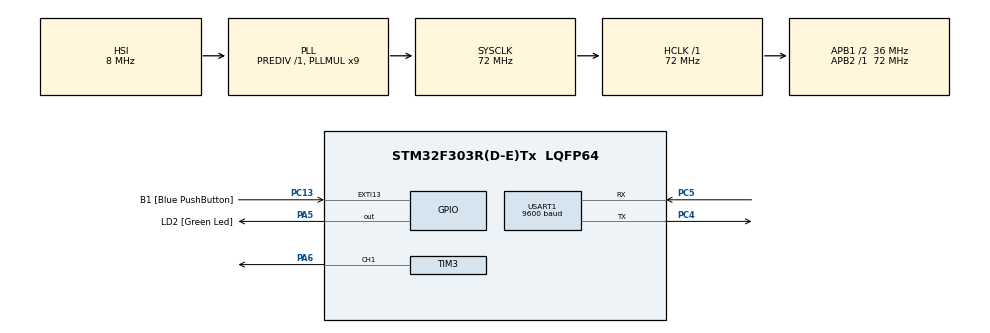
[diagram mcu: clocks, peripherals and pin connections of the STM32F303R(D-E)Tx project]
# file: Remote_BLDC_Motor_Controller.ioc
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Mcu.Family=STM32F3
PC15-OSC32_OUT.Mode=LSE-External-Oscillator
RCC.CortexFreq_Value=72000000
TIM3.AutoReloadPreload=TIM_AUTORELOAD_PRELOAD_ENABLE
USART1.BaudRate=9600
PC13.Signal=GPXTI13
PA14.GPIO_Label=TCK
RCC.SYSCLKSourceVirtual=RCC_SYSCLKSOURCE_PLLCLK
PC4.Signal=USART1_TX
PC5.Mode=Asynchronous
PC13.GPIO_Label=B1 [Blue PushButton]
RCC.APB1CLKDivider=RCC_HCLK_DIV2
PC14-OSC32_IN.Signal=RCC_OSC32_IN
ProjectManager.StackSize=0x400
USART1.VirtualMode-Asynchronous=VM_ASYNC
PA13.Signal=SYS_JTMS-SWDIO
ProjectManager.TargetToolchain=STM32CubeIDE
RCC.HCLKFreq_Value=72000000
RCC.APB2TimFreq_Value=72000000
TIM3.Period=19999
RCC.USBFreq_Value=72000000
PC15-OSC32_OUT.Signal=RCC_OSC32_OUT
RCC.AHBFreq_Value=72000000
PF0-OSC_IN.Mode=HSE-External-Clock-Source
TIM3.Channel-PWM\ Generation1\ CH1=TIM_CHANNEL_1
PA5.Signal=GPIO_Output
RCC.HSE_VALUE=8000000
board=NUCLEO-F303RE
RCC.RCC_PLLsource_Clock_Source_FROM_HSE=RCC_HSE_PREDIV_DIV2
RCC.PLLMUL=RCC_PLL_MUL9
RCC.APB2Freq_Value=72000000
PC14-OSC32_IN.Mode=LSE-External-Oscillator
PA14.Mode=Serial_Wire
TIM3.Prescaler=71
PA5.GPIO_PuPd=GPIO_NOPULL
SH.S_TIM3_CH1.0=TIM3_CH1,PWM Generation1 CH1
PA13.Mode=Serial_Wire
Mcu.Name=STM32F303R(D-E)Tx
PA13.GPIO_Label=TMS
PB3.Signal=SYS_JTDO-TRACESWO
RCC.SYSCLKFreq_VALUE=72000000
Mcu.Package=LQFP64
PA6.Signal=S_TIM3_CH1
PA5.GPIO_Label=LD2 [Green Led]
PC13.GPIO_ModeDefaultEXTI=GPIO_MODE_IT_FALLING
PA14.Signal=SYS_JTCK-SWCLK
ProjectManager.HeapSize=0x200
RCC.HSI_VALUE=8000000
RCC.PLLP=RCC_PLLP_DIV4
PA5.GPIO_Speed=GPIO_SPEED_FREQ_LOW
RCC.PLLQ=7
NVIC.PriorityGroup=NVIC_PRIORITYGROUP_0
RCC.PLLM=8
RCC.PLLN=336
RCC.APB1TimFreq_Value=72000000
PC5.Signal=USART1_RX
PF0-OSC_IN.Signal=RCC_OSC_IN
NVIC.USART1_IRQn=true\:0\:0\:false\:false\:true\:true\:true
RCC.APB1Freq_Value=36000000
PA5.GPIO_Mode=GPIO_MODE_OUTPUT_PP
VP_TIM3_VS_ClockSourceINT.Mode=Internal
PF1-OSC_OUT.Signal=RCC_OSC_OUT
PC4.Mode=Asynchronous
PB3.GPIO_Label=SWO

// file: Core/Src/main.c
/* USER CODE BEGIN Header */
/**
  ******************************************************************************
  * @file           : main.c
  * @brief          : Main program body
  ******************************************************************************
  * @attention
  *
  * <h2><center>&copy; Copyright (c) 2021 STMicroelectronics.
  * All rights reserved.</center></h2>
  *
  * This software component is licensed by ST under BSD 3-Clause license,
  * the "License"; You may not use this file except in compliance with the
  * License. You may obtain a copy of the License at:
  *                        opensource.org/licenses/BSD-3-Clause
  *
  ******************************************************************************
  */
/* USER CODE END Header */
#include "main.h"
#include "tim.h"
#include "usart.h"
#include "gpio.h"

/* USER CODE BEGIN PD */
#define MAX_THROTTLE_VALUE 100
#define THROTTLE_LEVEL(a)	(1000+(a)*10)
/* USER CODE END PD */

/* USER CODE BEGIN PV */
volatile uint8_t data = MAX_THROTTLE_VALUE;
/* USER CODE END PV */

void SystemClock_Config(void);

int main(void)
{

  /* MCU Configuration--------------------------------------------------------*/

  /* Reset of all peripherals, Initializes the Flash interface and the Systick. */
  HAL_Init();

  /* Configure the system clock */
  SystemClock_Config();

  /* Initialize all configured peripherals */
  MX_GPIO_Init();
  MX_USART1_UART_Init();
  MX_TIM3_Init();
  /* USER CODE BEGIN 2 */
  HAL_TIM_PWM_Start(&htim3, TIM_CHANNEL_1);
  HAL_UART_Receive_IT(&huart1, &data, sizeof(data));
  __HAL_TIM_SET_COMPARE(&htim3,TIM_CHANNEL_1, THROTTLE_LEVEL(data));
  /* USER CODE END 2 */

  /* Infinite loop */
  while (1)
  {

  }
}

void SystemClock_Config(void)
{
  RCC_OscInitTypeDef RCC_OscInitStruct = {0};
  RCC_ClkInitTypeDef RCC_ClkInitStruct = {0};
  RCC_PeriphCLKInitTypeDef PeriphClkInit = {0};

  /** Initializes the RCC Oscillators according to the specified parameters
  * in the RCC_OscInitTypeDef structure.
  */
  RCC_OscInitStruct.OscillatorType = RCC_OSCILLATORTYPE_HSI;
  RCC_OscInitStruct.HSIState = RCC_HSI_ON;
  RCC_OscInitStruct.HSICalibrationValue = RCC_HSICALIBRATION_DEFAULT;
  RCC_OscInitStruct.PLL.PLLState = RCC_PLL_ON;
  RCC_OscInitStruct.PLL.PLLSource = RCC_PLLSOURCE_HSI;
  RCC_OscInitStruct.PLL.PLLMUL = RCC_PLL_MUL9;
  RCC_OscInitStruct.PLL.PREDIV = RCC_PREDIV_DIV1;
  if (HAL_RCC_OscConfig(&RCC_OscInitStruct) != HAL_OK)
  {
    Error_Handler();
  }
  /** Initializes the CPU, AHB and APB buses clocks
  */
  RCC_ClkInitStruct.ClockType = RCC_CLOCKTYPE_HCLK|RCC_CLOCKTYPE_SYSCLK
                              |RCC_CLOCKTYPE_PCLK1|RCC_CLOCKTYPE_PCLK2;
  RCC_ClkInitStruct.SYSCLKSource = RCC_SYSCLKSOURCE_PLLCLK;
  RCC_ClkInitStruct.AHBCLKDivider = RCC_SYSCLK_DIV1;
  RCC_ClkInitStruct.APB1CLKDivider = RCC_HCLK_DIV2;
  RCC_ClkInitStruct.APB2CLKDivider = RCC_HCLK_DIV1;

  if (HAL_RCC_ClockConfig(&RCC_ClkInitStruct, FLASH_LATENCY_2) != HAL_OK)
  {
    Error_Handler();
  }
  PeriphClkInit.PeriphClockSelection = RCC_PERIPHCLK_USART1|RCC_PERIPHCLK_TIM34;
  PeriphClkInit.Usart1ClockSelection = RCC_USART1CLKSOURCE_PCLK2;
  PeriphClkInit.Tim34ClockSelection = RCC_TIM34CLK_HCLK;
  if (HAL_RCCEx_PeriphCLKConfig(&PeriphClkInit) != HAL_OK)
  {
    Error_Handler();
  }
}

/* USER CODE BEGIN 4 */
void HAL_UART_RxCpltCallback(UART_HandleTypeDef *huart)
{
	if(huart -> Instance == USART1)
	{
		HAL_GPIO_TogglePin(LD2_GPIO_Port, LD2_Pin);
		HAL_UART_Receive_IT(&huart1, &data, sizeof(data));
		__HAL_TIM_SET_COMPARE(&htim3,TIM_CHANNEL_1, THROTTLE_LEVEL(data));
	}
}
/* USER CODE END 4 */

void Error_Handler(void)
{
  __disable_irq();
  while (1)
  {
  }
}

/************************ (C) COPYRIGHT STMicroelectronics *****END OF FILE****/
